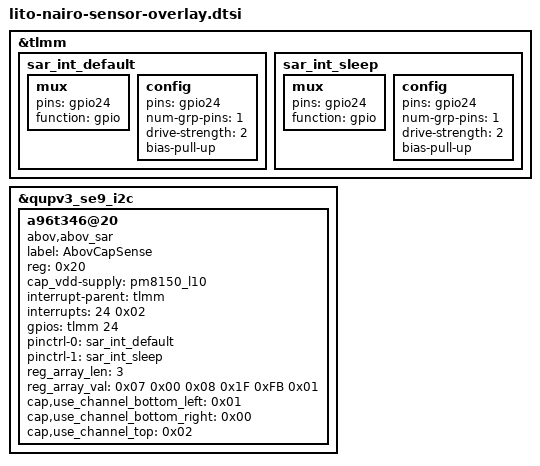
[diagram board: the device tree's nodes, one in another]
/* Copyright (c) 2019, The Linux Foundation. All rights reserved.
 *
 * This program is free software; you can redistribute it and/or modify
 * it under the terms of the GNU General Public License version 2 and
 * only version 2 as published by the Free Software Foundation.
 *
 * This program is distributed in the hope that it will be useful,
 * but WITHOUT ANY WARRANTY; without even the implied warranty of
 * MERCHANTABILITY or FITNESS FOR A PARTICULAR PURPOSE.  See the
 * GNU General Public License for more details.
 */

&tlmm {
	sar_int_default: sar_int_default {
			mux {
				pins = "gpio24";
				function =  "gpio";
			};
			config {
				pins = "gpio24";
				num-grp-pins = <1>;
				drive-strength = <2>;
				bias-pull-up;
			};
	};

	sar_int_sleep: sar_int_sleep {
			mux {
				pins = "gpio24";
				function =  "gpio";
			};
			config {
				pins = "gpio24";
				num-grp-pins = <1>;
				drive-strength = <2>;
				bias-pull-up;
			};
	};
};

&qupv3_se9_i2c {
	status = "ok";
	a96t346@20 {
		status = "ok";
		label = "AbovCapSense";
		compatible = "abov,abov_sar";
		reg = <0x20>;
		cap_vdd-supply = <&pm8150_l10>;
		interrupt-parent = <&tlmm>;
		interrupts = <24 0x02>;
		interrupt-names = "abov_irq";
		gpios = <&tlmm 24 0x02>;
		pinctrl-names = "default","sleep";
		pinctrl-0 = <&sar_int_default>;
		pinctrl-1 = <&sar_int_sleep>;
		reg_array_len = <3>;
		reg_array_val = <0x07 0x00 0x08 0x1F 0xFB 0x01>;
		cap,use_channel_bottom_left = <0x01>;
		cap,use_channel_bottom_right = <0x00>;
		cap,use_channel_top = <0x02>;
	};
};
